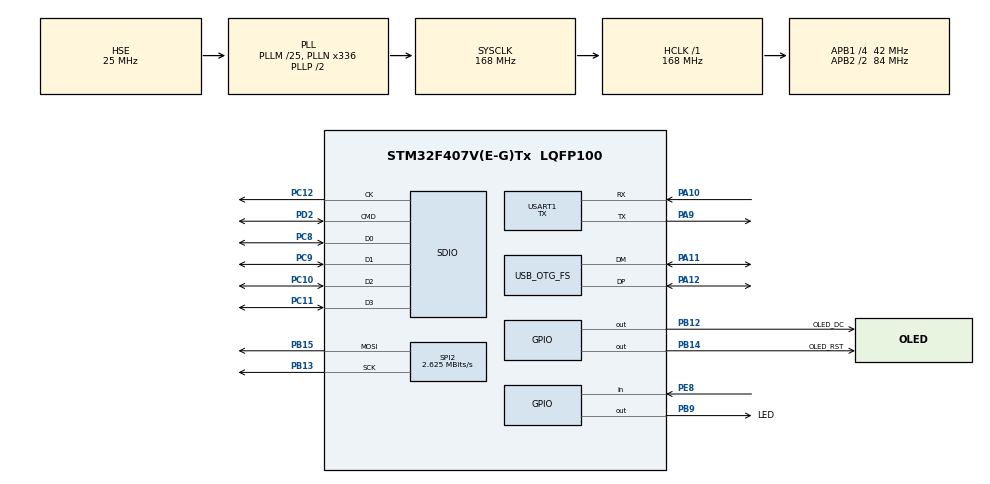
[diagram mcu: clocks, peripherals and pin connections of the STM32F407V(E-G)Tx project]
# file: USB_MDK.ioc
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Mcu.Family=STM32F4
Mcu.Name=STM32F407V(E-G)Tx
Mcu.Package=LQFP100
NVIC.OTG_FS_IRQn=true\:6\:0\:true\:false\:true\:false\:true\:true
NVIC.PriorityGroup=NVIC_PRIORITYGROUP_4
PA10.Mode=Asynchronous
PA10.Signal=USART1_RX
PA11.Mode=Device_Only
PA11.Signal=USB_OTG_FS_DM
PA12.Mode=Device_Only
PA12.Signal=USB_OTG_FS_DP
PA13.Mode=Serial_Wire
PA13.Signal=SYS_JTMS-SWDIO
PA14.Mode=Serial_Wire
PA14.Signal=SYS_JTCK-SWCLK
PA9.Mode=Asynchronous
PA9.Signal=USART1_TX
PB12.GPIO_Label=OLED_DC
PB12.Signal=GPIO_Output
PB13.Mode=TX_Only_Simplex_Unidirect_Master
PB13.Signal=SPI2_SCK
PB14.GPIO_Label=OLED_RST
PB14.Signal=GPIO_Output
PB15.Mode=TX_Only_Simplex_Unidirect_Master
PB15.Signal=SPI2_MOSI
PB9.GPIO_Label=LED
PB9.GPIO_ModeDefaultOutputPP=GPIO_MODE_OUTPUT_PP
PB9.GPIO_PuPd=GPIO_NOPULL
PB9.GPIO_Speed=GPIO_SPEED_FREQ_LOW
PB9.PinState=GPIO_PIN_SET
PB9.Signal=GPIO_Output
PC10.GPIO_PuPd=GPIO_NOPULL
PC10.Mode=SD_4_bits_Wide_bus
PC10.Signal=SDIO_D2
PC11.GPIO_PuPd=GPIO_NOPULL
PC11.Mode=SD_4_bits_Wide_bus
PC11.Signal=SDIO_D3
PC12.GPIO_PuPd=GPIO_NOPULL
PC12.Mode=SD_4_bits_Wide_bus
PC12.Signal=SDIO_CK
PC8.GPIO_PuPd=GPIO_NOPULL
PC8.Mode=SD_4_bits_Wide_bus
PC8.Signal=SDIO_D0
PC9.GPIO_PuPd=GPIO_NOPULL
PC9.Mode=SD_4_bits_Wide_bus
PC9.Signal=SDIO_D1
PD2.GPIO_PuPd=GPIO_NOPULL
PD2.Mode=SD_4_bits_Wide_bus
PD2.Signal=SDIO_CMD
PE8.Signal=GPIO_Input
PH0-OSC_IN.Mode=HSE-External-Oscillator
PH0-OSC_IN.Signal=RCC_OSC_IN
PH1-OSC_OUT.Mode=HSE-External-Oscillator
PH1-OSC_OUT.Signal=RCC_OSC_OUT
ProjectManager.HeapSize=0x8000
ProjectManager.StackSize=0x3000
ProjectManager.TargetToolchain=MDK-ARM V5.32
RCC.48MHZClocksFreq_Value=48000000
RCC.AHBFreq_Value=168000000
RCC.APB1CLKDivider=RCC_HCLK_DIV4
RCC.APB1Freq_Value=42000000
RCC.APB1TimFreq_Value=84000000
RCC.APB2CLKDivider=RCC_HCLK_DIV2
RCC.APB2Freq_Value=84000000
RCC.APB2TimFreq_Value=168000000
RCC.CortexFreq_Value=168000000
RCC.EnbaleCSS=true
RCC.HCLKFreq_Value=168000000
RCC.HSE_VALUE=25000000
RCC.HSI_VALUE=16000000
RCC.LSE_VALUE=32768
RCC.PLLM=25
RCC.PLLN=336
RCC.PLLQ=7
RCC.SYSCLKFreq_VALUE=168000000
RCC.SYSCLKSource=RCC_SYSCLKSOURCE_PLLCLK
RCC.VCOOutputFreq_Value=336000000
SDIO.ClockDiv=2
SDIO.ClockEdge=SDIO_CLOCK_EDGE_FALLING
SDIO.HardwareFlowControl=SDIO_HARDWARE_FLOW_CONTROL_ENABLE
SPI2.BaudRatePrescaler=SPI_BAUDRATEPRESCALER_16
SPI2.CLKPhase=SPI_PHASE_2EDGE
SPI2.CLKPolarity=SPI_POLARITY_HIGH
SPI2.CalculateBaudRate=2.625 MBits/s
SPI2.Direction=SPI_DIRECTION_2LINES
SPI2.Mode=SPI_MODE_MASTER
SPI2.VirtualType=VM_MASTER
STMicroelectronics.X-CUBE-DISPLAY.2.0.1_IsPackSelfContextualization=true
USART1.Mode=MODE_TX
USART1.VirtualMode=VM_ASYNC
USB_DEVICE.CLASS_NAME_FS=MSC
USB_DEVICE.MSC_MEDIA_PACKET-MSC_FS=4096
USB_DEVICE.PID_MSC_FS=22345
USB_DEVICE.USBD_MAX_NUM_CONFIGURATION-MSC_FS=1
USB_DEVICE.USBD_MAX_NUM_INTERFACES-MSC_FS=1
USB_DEVICE.USBD_SELF_POWERED-MSC_FS=1
USB_DEVICE.VirtualMode-MSC_FS=Msc
USB_DEVICE.VirtualModeFS=Msc_FS
USB_OTG_FS.VirtualMode=Device_Only
VP_USB_DEVICE_VS_USB_DEVICE_MSC_FS.Mode=MSC_FS
board=custom

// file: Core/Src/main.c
/* USER CODE BEGIN Header */
/**
  ******************************************************************************
  * @file           : main.c
  * @brief          : Main program body
  ******************************************************************************
  * @attention
  *
  * Copyright (c) 2022 STMicroelectronics.
  * All rights reserved.
  *
  * This software is licensed under terms that can be found in the LICENSE file
  * in the root directory of this software component.
  * If no LICENSE file comes with this software, it is provided AS-IS.
  *
  ******************************************************************************
  */
/* USER CODE END Header */
#include "main.h"
#include "sdio.h"
#include "spi.h"
#include "usart.h"
#include "usb_device.h"
#include "gpio.h"

void SystemClock_Config(void);

/* USER CODE BEGIN 0 */

int fputc(int c, FILE *stream)    //重写fputc函数
{
 /*
    huart1是工具生成代码定义的UART1结构体，
    如果以后要使用其他串口打印，只需要把这个结构体改成其他UART结构体。
*/
    HAL_UART_Transmit(&huart1, (unsigned char *)&c, 1, 1000);
    return 1;
}
/* USER CODE END 0 */

int main(void)
{

  /* MCU Configuration--------------------------------------------------------*/

  /* Reset of all peripherals, Initializes the Flash interface and the Systick. */
  HAL_Init();

  /* Configure the system clock */
  SystemClock_Config();

  /* Initialize all configured peripherals */
  MX_GPIO_Init();
  MX_USB_DEVICE_Init();
  MX_SDIO_SD_Init();
  MX_USART1_UART_Init();
  MX_SPI2_Init();
  /* USER CODE BEGIN 2 */

  u8g2_Init();

  /* USER CODE END 2 */

  /* Infinite loop */
  /* USER CODE BEGIN WHILE */

 Start_Page();
 Display_FreeRTOS_Logo();
 Display_NIUNI();
  while (1)
  {

    HAL_Delay(50);
    HAL_GPIO_WritePin(LED_GPIO_Port, LED_Pin, GPIO_PIN_SET);
    HAL_Delay(50);
    HAL_GPIO_WritePin(LED_GPIO_Port, LED_Pin, GPIO_PIN_RESET);
  // printf("状态查询：%d   \r\n", HAL_SD_GetCardState(&hsd) );

    /* USER CODE END WHILE */

  }
}

void SystemClock_Config(void)
{
  RCC_OscInitTypeDef RCC_OscInitStruct = {0};
  RCC_ClkInitTypeDef RCC_ClkInitStruct = {0};

  /** Configure the main internal regulator output voltage
  */
  __HAL_RCC_PWR_CLK_ENABLE();
  __HAL_PWR_VOLTAGESCALING_CONFIG(PWR_REGULATOR_VOLTAGE_SCALE1);

  /** Initializes the RCC Oscillators according to the specified parameters
  * in the RCC_OscInitTypeDef structure.
  */
  RCC_OscInitStruct.OscillatorType = RCC_OSCILLATORTYPE_HSE;
  RCC_OscInitStruct.HSEState = RCC_HSE_ON;
  RCC_OscInitStruct.PLL.PLLState = RCC_PLL_ON;
  RCC_OscInitStruct.PLL.PLLSource = RCC_PLLSOURCE_HSE;
  RCC_OscInitStruct.PLL.PLLM = 25;
  RCC_OscInitStruct.PLL.PLLN = 336;
  RCC_OscInitStruct.PLL.PLLP = RCC_PLLP_DIV2;
  RCC_OscInitStruct.PLL.PLLQ = 7;
  if (HAL_RCC_OscConfig(&RCC_OscInitStruct) != HAL_OK)
  {
    Error_Handler();
  }

  /** Initializes the CPU, AHB and APB buses clocks
  */
  RCC_ClkInitStruct.ClockType = RCC_CLOCKTYPE_HCLK|RCC_CLOCKTYPE_SYSCLK
                              |RCC_CLOCKTYPE_PCLK1|RCC_CLOCKTYPE_PCLK2;
  RCC_ClkInitStruct.SYSCLKSource = RCC_SYSCLKSOURCE_PLLCLK;
  RCC_ClkInitStruct.AHBCLKDivider = RCC_SYSCLK_DIV1;
  RCC_ClkInitStruct.APB1CLKDivider = RCC_HCLK_DIV4;
  RCC_ClkInitStruct.APB2CLKDivider = RCC_HCLK_DIV2;

  if (HAL_RCC_ClockConfig(&RCC_ClkInitStruct, FLASH_LATENCY_5) != HAL_OK)
  {
    Error_Handler();
  }

  /** Enables the Clock Security System
  */
  HAL_RCC_EnableCSS();
}

void Error_Handler(void)
{
  __disable_irq();
  while (1)
  {
  }
}
